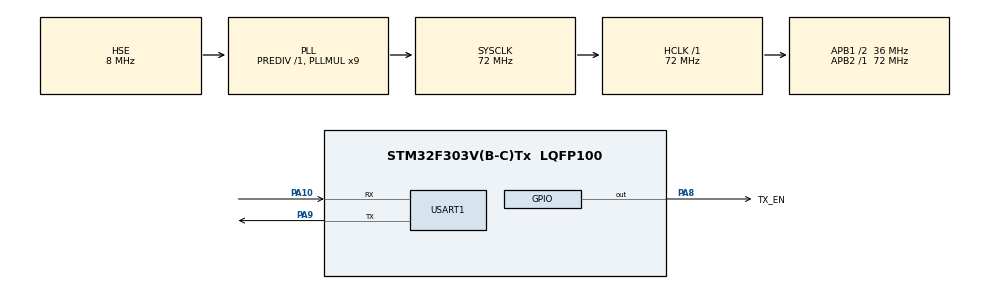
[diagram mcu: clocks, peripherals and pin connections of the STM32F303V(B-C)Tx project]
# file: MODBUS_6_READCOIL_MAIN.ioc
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Mcu.Family=STM32F3
Mcu.Name=STM32F303V(B-C)Tx
Mcu.Package=LQFP100
NVIC.PriorityGroup=NVIC_PRIORITYGROUP_0
NVIC.USART1_IRQn=true\:0\:0\:false\:false\:true\:true\:true\:true
PA10.Mode=Asynchronous
PA10.Signal=USART1_RX
PA13.Mode=Serial_Wire
PA13.Signal=SYS_JTMS-SWDIO
PA14.Mode=Serial_Wire
PA14.Signal=SYS_JTCK-SWCLK
PA8.GPIO_Label=TX_EN
PA8.Signal=GPIO_Output
PA9.Mode=Asynchronous
PA9.Signal=USART1_TX
PF0-OSC_IN.Mode=HSE-External-Oscillator
PF0-OSC_IN.Signal=RCC_OSC_IN
PF1-OSC_OUT.Mode=HSE-External-Oscillator
PF1-OSC_OUT.Signal=RCC_OSC_OUT
ProjectManager.HeapSize=0x200
ProjectManager.StackSize=0x400
ProjectManager.TargetToolchain=STM32CubeIDE
RCC.AHBFreq_Value=72000000
RCC.APB1CLKDivider=RCC_HCLK_DIV2
RCC.APB1Freq_Value=36000000
RCC.APB1TimFreq_Value=72000000
RCC.APB2Freq_Value=72000000
RCC.APB2TimFreq_Value=72000000
RCC.CortexFreq_Value=72000000
RCC.HCLKFreq_Value=72000000
RCC.HSE_VALUE=8000000
RCC.HSI_VALUE=8000000
RCC.LSE_VALUE=32768
RCC.PLLMUL=RCC_PLL_MUL9
RCC.PLLSourceVirtual=RCC_PLLSOURCE_HSE
RCC.SYSCLKFreq_VALUE=72000000
RCC.SYSCLKSourceVirtual=RCC_SYSCLKSOURCE_PLLCLK
RCC.USBFreq_Value=72000000
USART1.VirtualMode-Asynchronous=VM_ASYNC
board=STM32F3DISCOVERY

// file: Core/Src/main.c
/* USER CODE BEGIN Header */
/**
  ******************************************************************************
  * @file           : main.c
  * @brief          : Main program body
  ******************************************************************************
  * @attention
  *
  * Copyright (c) 2023 STMicroelectronics.
  * All rights reserved.
  *
  * This software is licensed under terms that can be found in the LICENSE file
  * in the root directory of this software component.
  * If no LICENSE file comes with this software, it is provided AS-IS.
  *
  ******************************************************************************
  */
/* USER CODE END Header */
#include "main.h"
#include "modbus_crc.h"

 UART_HandleTypeDef huart1;

void SystemClock_Config(void);
static void MX_GPIO_Init(void);
static void MX_USART1_UART_Init(void);

/* USER CODE BEGIN 0 */
uint8_t TxData[8];
uint8_t RxData[16];

int Data[16]; // in the multiple of 8
int indx = 0;

void sendData (uint8_t *data)
{
	HAL_GPIO_WritePin(TX_EN_GPIO_Port, TX_EN_Pin, GPIO_PIN_SET);
	HAL_UART_Transmit(&huart1, data, 8, 1000);
	HAL_GPIO_WritePin(TX_EN_GPIO_Port,TX_EN_Pin , GPIO_PIN_RESET);
}

void HAL_UARTEx_RxEventCallback(UART_HandleTypeDef *huart, uint16_t Size)
{
	for(int j = 0 ; j < RxData[2]; j++)
	{
		for(int i = 0; i<8;i++)
		{
			Data[indx++] = ((RxData[3+j]>>i)&1);
		}
	}
}

/* USER CODE END 0 */

int main(void)
{

  /* MCU Configuration--------------------------------------------------------*/

  /* Reset of all peripherals, Initializes the Flash interface and the Systick. */
  HAL_Init();

  /* Configure the system clock */
  SystemClock_Config();

  /* Initialize all configured peripherals */
  MX_GPIO_Init();
  MX_USART1_UART_Init();
  /* USER CODE BEGIN 2 */
  HAL_UARTEx_ReceiveToIdle_IT(&huart1, RxData, 16);

  TxData[0] = 0x05;
  TxData[1] = 0x01;       //function code for read coil

  TxData[2] = 0;
  TxData[3] = 0x01;       // the coil address will be 00000000 00000001 = 1 + 1 = 2

  TxData[4] = 0;
  TxData[5] = 10;          // the no. of coils to read will be 00000000 0001000 =  8 coils = 1 byte

  uint16_t crc = crc16(TxData, 6);
  TxData[6] =  crc&0xFF;
  TxData[7] =  (crc>>8)& 0xFF;

  sendData(TxData);

  /* USER CODE END 2 */

  /* Infinite loop */
  while (1)
  {

  }
}

void SystemClock_Config(void)
{
  RCC_OscInitTypeDef RCC_OscInitStruct = {0};
  RCC_ClkInitTypeDef RCC_ClkInitStruct = {0};
  RCC_PeriphCLKInitTypeDef PeriphClkInit = {0};

  /** Initializes the RCC Oscillators according to the specified parameters
  * in the RCC_OscInitTypeDef structure.
  */
  RCC_OscInitStruct.OscillatorType = RCC_OSCILLATORTYPE_HSE;
  RCC_OscInitStruct.HSEState = RCC_HSE_ON;
  RCC_OscInitStruct.HSEPredivValue = RCC_HSE_PREDIV_DIV1;
  RCC_OscInitStruct.HSIState = RCC_HSI_ON;
  RCC_OscInitStruct.PLL.PLLState = RCC_PLL_ON;
  RCC_OscInitStruct.PLL.PLLSource = RCC_PLLSOURCE_HSE;
  RCC_OscInitStruct.PLL.PLLMUL = RCC_PLL_MUL9;
  if (HAL_RCC_OscConfig(&RCC_OscInitStruct) != HAL_OK)
  {
    Error_Handler();
  }

  /** Initializes the CPU, AHB and APB buses clocks
  */
  RCC_ClkInitStruct.ClockType = RCC_CLOCKTYPE_HCLK|RCC_CLOCKTYPE_SYSCLK
                              |RCC_CLOCKTYPE_PCLK1|RCC_CLOCKTYPE_PCLK2;
  RCC_ClkInitStruct.SYSCLKSource = RCC_SYSCLKSOURCE_PLLCLK;
  RCC_ClkInitStruct.AHBCLKDivider = RCC_SYSCLK_DIV1;
  RCC_ClkInitStruct.APB1CLKDivider = RCC_HCLK_DIV2;
  RCC_ClkInitStruct.APB2CLKDivider = RCC_HCLK_DIV1;

  if (HAL_RCC_ClockConfig(&RCC_ClkInitStruct, FLASH_LATENCY_2) != HAL_OK)
  {
    Error_Handler();
  }
  PeriphClkInit.PeriphClockSelection = RCC_PERIPHCLK_USART1;
  PeriphClkInit.Usart1ClockSelection = RCC_USART1CLKSOURCE_PCLK2;
  if (HAL_RCCEx_PeriphCLKConfig(&PeriphClkInit) != HAL_OK)
  {
    Error_Handler();
  }
}

static void MX_USART1_UART_Init(void)
{

  huart1.Instance = USART1;
  huart1.Init.BaudRate = 38400;
  huart1.Init.WordLength = UART_WORDLENGTH_8B;
  huart1.Init.StopBits = UART_STOPBITS_1;
  huart1.Init.Parity = UART_PARITY_NONE;
  huart1.Init.Mode = UART_MODE_TX_RX;
  huart1.Init.HwFlowCtl = UART_HWCONTROL_NONE;
  huart1.Init.OverSampling = UART_OVERSAMPLING_16;
  huart1.Init.OneBitSampling = UART_ONE_BIT_SAMPLE_DISABLE;
  huart1.AdvancedInit.AdvFeatureInit = UART_ADVFEATURE_NO_INIT;
  if (HAL_UART_Init(&huart1) != HAL_OK)
  {
    Error_Handler();
  }

}

static void MX_GPIO_Init(void)
{
  GPIO_InitTypeDef GPIO_InitStruct = {0};

  /* GPIO Ports Clock Enable */
  __HAL_RCC_GPIOF_CLK_ENABLE();
  __HAL_RCC_GPIOA_CLK_ENABLE();

  /*Configure GPIO pin Output Level */
  HAL_GPIO_WritePin(TX_EN_GPIO_Port, TX_EN_Pin, GPIO_PIN_RESET);

  /*Configure GPIO pin : TX_EN_Pin */
  GPIO_InitStruct.Pin = TX_EN_Pin;
  GPIO_InitStruct.Mode = GPIO_MODE_OUTPUT_PP;
  GPIO_InitStruct.Pull = GPIO_NOPULL;
  GPIO_InitStruct.Speed = GPIO_SPEED_FREQ_LOW;
  HAL_GPIO_Init(TX_EN_GPIO_Port, &GPIO_InitStruct);

}

void Error_Handler(void)
{
  __disable_irq();
  while (1)
  {
  }
}
